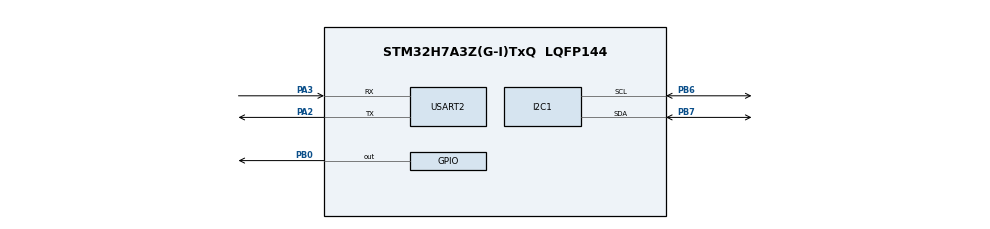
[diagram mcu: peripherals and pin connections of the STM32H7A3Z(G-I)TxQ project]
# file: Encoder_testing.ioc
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CORTEX_M7.default_mode_Activation=1
I2C1.Timing=0x00707CBB
Mcu.Family=STM32H7
Mcu.Name=STM32H7A3Z(G-I)TxQ
Mcu.Package=LQFP144
NVIC.PriorityGroup=NVIC_PRIORITYGROUP_4
PA2.Mode=Asynchronous
PA2.Signal=USART2_TX
PA3.Mode=Asynchronous
PA3.Signal=USART2_RX
PB0.Signal=GPIO_Output
PB6.GPIO_Pu=GPIO_PULLUP
PB6.Mode=I2C
PB6.Signal=I2C1_SCL
PB7.GPIO_Pu=GPIO_PULLUP
PB7.Mode=I2C
PB7.Signal=I2C1_SDA
ProjectManager.HeapSize=0x200
ProjectManager.StackSize=0x400
ProjectManager.TargetToolchain=STM32CubeIDE
RCC.ADCFreq_Value=129000000
RCC.APB1Freq_Value=32000000
RCC.APB2Freq_Value=64000000
RCC.APB3Freq_Value=64000000
RCC.APB4Freq_Value=64000000
RCC.CDPPRE1=RCC_APB1_DIV2
RCC.CortexFreq_Value=64000000
RCC.HCLKFreq_Value=64000000
RCC.SYSCLKFreq_VALUE=64000000
RCC.USBFreq_Value=129000000
USART2.VirtualMode-Asynchronous=VM_ASYNC
VP_MEMORYMAP_VS_MEMORYMAP.Mode=CurAppReg
board=custom

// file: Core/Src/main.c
/* USER CODE BEGIN Header */
/**
  ******************************************************************************
  * @file           : main.c
  * @brief          : Main program body
  ******************************************************************************
  * @attention
  *
  * Copyright (c) 2025 STMicroelectronics.
  * All rights reserved.
  *
  * This software is licensed under terms that can be found in the LICENSE file
  * in the root directory of this software component.
  * If no LICENSE file comes with this software, it is provided AS-IS.
  *
  ******************************************************************************
  */
/* USER CODE END Header */
#include "main.h"
#include "i2c.h"
#include "usart.h"
#include "gpio.h"
#include "as5600.h"

/* USER CODE BEGIN PV */
uint8_t testing ;

/* USER CODE END PV */

void SystemClock_Config(void);
static void MPU_Config(void);

int main(void)
{

  /* MPU Configuration--------------------------------------------------------*/
  MPU_Config();

  /* MCU Configuration--------------------------------------------------------*/

  /* Reset of all peripherals, Initializes the Flash interface and the Systick. */
  HAL_Init();

  /* Configure the system clock */
  SystemClock_Config();

  /* Initialize all configured peripherals */
  MX_GPIO_Init();
  MX_I2C1_Init();
  MX_USART2_UART_Init();
  *encoder = (EncoderStruct){0};

  /* Infinite loop */
  while (1)
  {
	  testing = AS5600_CheckConnection();
	  AS5600_MakeSmooth(encoder);
	  AS5600_ReadRawAngle(encoder);
	  AS5600_WriteZPOS(encoder);
	  AS5600_ReadZPOS(encoder);
	  HAL_Delay(100);

	  AS5600_ReadRawAngle(encoder);
	  AS5600_WriteMPOS(encoder);
	  AS5600_ReadMPOS(encoder);

	  HAL_GPIO_TogglePin(GPIOB, GPIO_PIN_0);
	  HAL_Delay(1000); /* 1000 ms on/off -> 2 Hz blink */
  }
}

void SystemClock_Config(void)
{
  RCC_OscInitTypeDef RCC_OscInitStruct = {0};
  RCC_ClkInitTypeDef RCC_ClkInitStruct = {0};

  /*AXI clock gating */
  RCC->CKGAENR = 0xE003FFFF;

  /** Supply configuration update enable
  */
  HAL_PWREx_ConfigSupply(PWR_DIRECT_SMPS_SUPPLY);

  /** Configure the main internal regulator output voltage
  */
  __HAL_PWR_VOLTAGESCALING_CONFIG(PWR_REGULATOR_VOLTAGE_SCALE3);

  while(!__HAL_PWR_GET_FLAG(PWR_FLAG_VOSRDY)) {}

  /** Initializes the RCC Oscillators according to the specified parameters
  * in the RCC_OscInitTypeDef structure.
  */
  RCC_OscInitStruct.OscillatorType = RCC_OSCILLATORTYPE_HSI;
  RCC_OscInitStruct.HSIState = RCC_HSI_DIV1;
  RCC_OscInitStruct.HSICalibrationValue = 64;
  RCC_OscInitStruct.PLL.PLLState = RCC_PLL_NONE;
  if (HAL_RCC_OscConfig(&RCC_OscInitStruct) != HAL_OK)
  {
    Error_Handler();
  }

  /** Initializes the CPU, AHB and APB buses clocks
  */
  RCC_ClkInitStruct.ClockType = RCC_CLOCKTYPE_HCLK|RCC_CLOCKTYPE_SYSCLK
                              |RCC_CLOCKTYPE_PCLK1|RCC_CLOCKTYPE_PCLK2
                              |RCC_CLOCKTYPE_D3PCLK1|RCC_CLOCKTYPE_D1PCLK1;
  RCC_ClkInitStruct.SYSCLKSource = RCC_SYSCLKSOURCE_HSI;
  RCC_ClkInitStruct.SYSCLKDivider = RCC_SYSCLK_DIV1;
  RCC_ClkInitStruct.AHBCLKDivider = RCC_HCLK_DIV1;
  RCC_ClkInitStruct.APB3CLKDivider = RCC_APB3_DIV1;
  RCC_ClkInitStruct.APB1CLKDivider = RCC_APB1_DIV2;
  RCC_ClkInitStruct.APB2CLKDivider = RCC_APB2_DIV1;
  RCC_ClkInitStruct.APB4CLKDivider = RCC_APB4_DIV1;

  if (HAL_RCC_ClockConfig(&RCC_ClkInitStruct, FLASH_LATENCY_2) != HAL_OK)
  {
    Error_Handler();
  }
}

 /* MPU Configuration */

void MPU_Config(void)
{
  MPU_Region_InitTypeDef MPU_InitStruct = {0};

  /* Disables the MPU */
  HAL_MPU_Disable();

  /** Initializes and configures the Region and the memory to be protected
  */
  MPU_InitStruct.Enable = MPU_REGION_ENABLE;
  MPU_InitStruct.Number = MPU_REGION_NUMBER0;
  MPU_InitStruct.BaseAddress = 0x0;
  MPU_InitStruct.Size = MPU_REGION_SIZE_4GB;
  MPU_InitStruct.SubRegionDisable = 0x87;
  MPU_InitStruct.TypeExtField = MPU_TEX_LEVEL0;
  MPU_InitStruct.AccessPermission = MPU_REGION_NO_ACCESS;
  MPU_InitStruct.DisableExec = MPU_INSTRUCTION_ACCESS_DISABLE;
  MPU_InitStruct.IsShareable = MPU_ACCESS_SHAREABLE;
  MPU_InitStruct.IsCacheable = MPU_ACCESS_NOT_CACHEABLE;
  MPU_InitStruct.IsBufferable = MPU_ACCESS_NOT_BUFFERABLE;

  HAL_MPU_ConfigRegion(&MPU_InitStruct);
  /* Enables the MPU */
  HAL_MPU_Enable(MPU_PRIVILEGED_DEFAULT);

}

void Error_Handler(void)
{
  __disable_irq();
  while (1)
  {
  }
}
